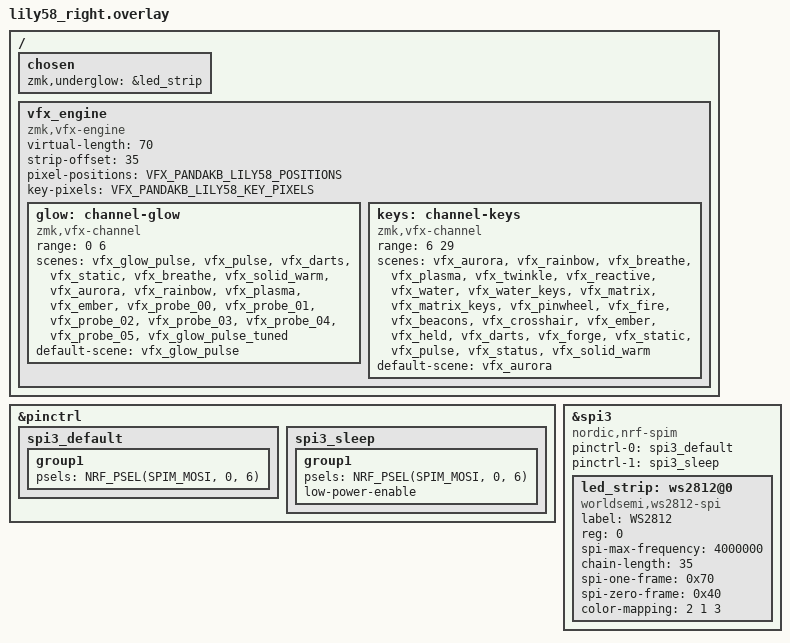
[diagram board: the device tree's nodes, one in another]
#include <dt-bindings/zmk/vfx.h>
#include <vfx/pandakb-lily58.dtsi>
#include <vfx/presets.dtsi>
#include "vfx-probe.dtsi"
#include "vfx-tunable.dtsi"

/*
 * PandaKB Lily58 MX RGB underglow on nice_nano, right half.
 *
 * Filename matters: ZMK looks for <shield>_<board>.overlay or
 * <shield>.overlay, so this has to be lily58_left.overlay to be applied at
 * all. The right half is the same but for strip-offset.
 */

&pinctrl {
    spi3_default: spi3_default {
        group1 {
            psels = <NRF_PSEL(SPIM_MOSI, 0, 6)>;
        };
    };

    spi3_sleep: spi3_sleep {
        group1 {
            psels = <NRF_PSEL(SPIM_MOSI, 0, 6)>;
            low-power-enable;
        };
    };
};

&spi3 {
    compatible = "nordic,nrf-spim";
    status = "okay";

    pinctrl-0 = <&spi3_default>;
    pinctrl-1 = <&spi3_sleep>;
    pinctrl-names = "default", "sleep";

    led_strip: ws2812@0 {
        compatible = "worldsemi,ws2812-spi";
        label = "WS2812";

        /* SPI */
        reg = <0>; /* required for SPI bindings */
        spi-max-frequency = <4000000>;

        /* WS2812 */
        chain-length = <35>;
        spi-one-frame = <0x70>;
        spi-zero-frame = <0x40>;
        /* GREEN RED BLUE, the order SK6812 takes its bytes in. These are
         * Zephyr's LED_COLOR_ID values, where 0 is WHITE and red starts at 1,
         * so the old <1 0 2> read as RED WHITE GREEN: it fed the chip's red
         * line a constant 0 and never sent blue at all.
         */
        color-mapping = <2 1 3>;
    };
};

/ {
    chosen {
        zmk,underglow = &led_strip;
    };

    /* Effects are positioned across the whole keyboard, so each half renders
     * its own slice of a 70 pixel space and gradients carry across the seam.
     * The left half starts at 0; the right half starts at 35.
     */
    vfx_engine: vfx_engine {
        compatible = "zmk,vfx-engine";
        status = "okay";

        virtual-length = <70>;
        strip-offset = <35>;

        /* This board chains 6 downward-facing underglow LEDs before its 29
         * per-key ones, so neither the positions nor the key map follow the
         * plain 6x6 grid the generic Lily58 list assumes.
         */
        pixel-positions = <VFX_PANDAKB_LILY58_POSITIONS>;

        /* Without this a ripple starts at whatever pixel shares a number with
         * the key position, which is why pressing N lit the LED under 9.
         */
        key-pixels = <VFX_PANDAKB_LILY58_KEY_PIXELS>;

        /* The two halves must declare the same channels carrying the same
         * scenes in the same order. Next and previous are resolved to an
         * absolute index on the central and relayed as a number, so halves
         * that disagree land on different scenes.
         *
         * Declaration order is the channel id the keymap addresses: glow is
         * 0, keys is 1. There is no engine-wide default-scene any more, since
         * each channel brings its own.
         */
        glow: channel-glow {
            compatible = "zmk,vfx-channel";
            range = <0 6>;

            /* Reactive here means reacting to a press at all, not to where it
             * landed: these pixels sit behind the board, so the ones that aim
             * at a key have nothing to say on them. Nor do the indicators,
             * which need more than six pixels to read.
             */
            scenes = <&vfx_glow_pulse &vfx_pulse &vfx_darts &vfx_static
                      &vfx_breathe &vfx_solid_warm &vfx_aurora &vfx_rainbow &vfx_plasma
                      &vfx_ember
                      &vfx_probe_00 &vfx_probe_01 &vfx_probe_02
                      &vfx_probe_03 &vfx_probe_04 &vfx_probe_05
                      &vfx_glow_pulse_tuned>;
            default-scene = <&vfx_glow_pulse>;
        };

        keys: channel-keys {
            compatible = "zmk,vfx-channel";
            range = <6 29>;

            scenes = <&vfx_aurora &vfx_rainbow &vfx_breathe &vfx_plasma &vfx_twinkle
                      &vfx_reactive &vfx_water &vfx_water_keys &vfx_matrix &vfx_matrix_keys
                      &vfx_pinwheel &vfx_fire &vfx_beacons &vfx_crosshair &vfx_ember
                      &vfx_held &vfx_darts &vfx_forge &vfx_static &vfx_pulse
                      &vfx_status &vfx_solid_warm>;
            default-scene = <&vfx_aurora>;
        };
    };
};
